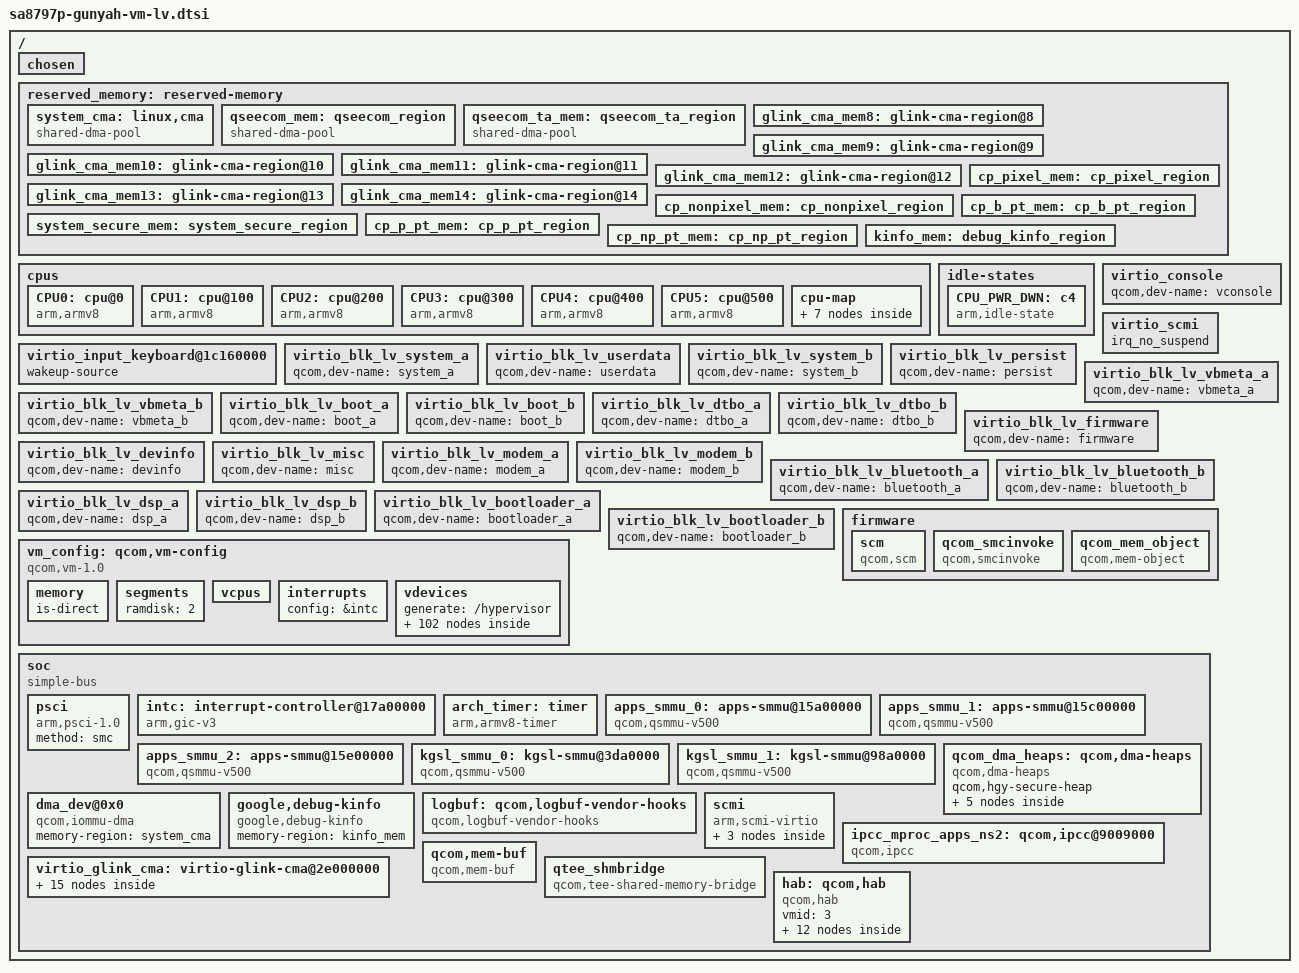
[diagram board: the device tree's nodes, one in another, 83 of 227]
// SPDX-License-Identifier: BSD-3-Clause
/*
 * Copyright (c) Qualcomm Technologies, Inc. and/or its subsidiaries.
 */

#include <dt-bindings/interrupt-controller/arm-gic.h>
#include <dt-bindings/arm/msm/qcom_dma_heap_dt_constants.h>
#include <dt-bindings/mailbox/qcom-ipcc.h>
#include <dt-bindings/soc/qcom,ipcc.h>
#include <dt-bindings/mailbox/qcom-ipcc-sa8797p.h>

/ {
	#address-cells = <0x2>;
	#size-cells = <0x2>;
	qcom,msm-name = "SA_GUNYAH_VM";
	interrupt-parent = <&intc>;

	chosen {
		bootargs = "nokaslr log_buf_len=1M console=hvc0 driver_async_probe=arm-scmi";
	};

	reserved_memory: reserved-memory {
		#address-cells = <2>;
		#size-cells = <2>;
		ranges;

		system_cma: linux,cma {
			compatible = "shared-dma-pool";
			alloc-ranges = <0x0 0x0 0x0 0xffffffff>;
			reusable;
			alignment = <0x0 0x400000>;
			size = <0x0 0x2000000>;
			linux,cma-default;
		};

		qseecom_mem: qseecom_region {
			compatible = "shared-dma-pool";
			alloc-ranges = <0x0 0x00000000 0x0 0xffffffff>;
			reusable;
			alignment = <0x0 0x400000>;
			size = <0x0 0x1400000>;
		};

		qseecom_ta_mem: qseecom_ta_region {
			compatible = "shared-dma-pool";
			alloc-ranges = <0x0 0x00000000 0x0 0xffffffff>;
			reusable;
			alignment = <0x0 0x400000>;
			size = <0x0 0x1000000>;
		};

		glink_cma_mem8: glink-cma-region@8 {
			no-map;
			qcom,label = <0x150>;
		};

		glink_cma_mem9: glink-cma-region@9 {
			no-map;
			qcom,label = <0x151>;
		};

		glink_cma_mem10: glink-cma-region@10 {
			no-map;
			qcom,label = <0x152>;
		};

		glink_cma_mem11: glink-cma-region@11 {
			no-map;
			qcom,label = <0x153>;
		};

		glink_cma_mem12: glink-cma-region@12 {
			no-map;
			qcom,label = <0x154>;
		};

		glink_cma_mem13: glink-cma-region@13 {
			no-map;
			qcom,label = <0x155>;
		};

		glink_cma_mem14: glink-cma-region@14 {
			no-map;
			qcom,label = <0x156>;
		};

		cp_pixel_mem: cp_pixel_region {
			no-map;
			qcom,target-vmid = <0xa>;
			qcom,label = <0xD0A>;
			qcom,unmapped;
		};

		cp_nonpixel_mem: cp_nonpixel_region {
			no-map;
			qcom,target-vmid = <0xb>;
			qcom,label = <0xD0B>;
			qcom,unmapped;
		};

		system_secure_mem: system_secure_region {
			no-map;
			qcom,target-vmid = <0x9>;
			qcom,label = <0xD09>;
			qcom,unmapped;
		};

		cp_b_pt_mem: cp_b_pt_region {
			qcom,label = <0x9D>;
			qcom,secure-pt-reserved;
		};

		cp_p_pt_mem: cp_p_pt_region {
			qcom,label = <0x9E>;
			qcom,secure-pt-reserved;
		};

		cp_np_pt_mem: cp_np_pt_region {
			qcom,label = <0x9F>;
			qcom,secure-pt-reserved;
		};

		kinfo_mem: debug_kinfo_region {
			alloc-ranges = <0x0 0x0 0xffffffff 0xffffffff>;
			size = <0x0 0x1000>;
			no-map;
		};
	};

	cpus {
		#address-cells = <0x2>;
		#size-cells = <0x0>;

		CPU0: cpu@0 {
			compatible = "arm,armv8";
			reg = <0x0 0x0>;
			device_type = "cpu";
			enable-method = "psci";
			cpu-idle-states = <&CPU_PWR_DWN>;
		};

		CPU1: cpu@100 {
			compatible = "arm,armv8";
			reg = <0x0 0x100>;
			device_type = "cpu";
			enable-method = "psci";
			cpu-idle-states = <&CPU_PWR_DWN>;
		};

		CPU2: cpu@200 {
			compatible = "arm,armv8";
			reg = <0x0 0x200>;
			device_type = "cpu";
			enable-method = "psci";
			cpu-idle-states = <&CPU_PWR_DWN>;
		};

		CPU3: cpu@300 {
			compatible = "arm,armv8";
			reg = <0x0 0x300>;
			device_type = "cpu";
			enable-method = "psci";
			cpu-idle-states = <&CPU_PWR_DWN>;
		};

		CPU4: cpu@400 {
			compatible = "arm,armv8";
			reg = <0x0 0x400>;
			device_type = "cpu";
			enable-method = "psci";
			cpu-idle-states = <&CPU_PWR_DWN>;
		};

		CPU5: cpu@500 {
			compatible = "arm,armv8";
			reg = <0x0 0x500>;
			device_type = "cpu";
			enable-method = "psci";
			cpu-idle-states = <&CPU_PWR_DWN>;
		};

		cpu-map {
			cluster0 {
				core0 {
					cpu = <&CPU0>;
				};

				core1 {
					cpu = <&CPU1>;
				};

				core2 {
					cpu = <&CPU2>;
				};

				core3 {
					cpu = <&CPU3>;
				};

				core4 {
					cpu = <&CPU4>;
				};

				core5 {
					cpu = <&CPU5>;
				};
			};
		};
	};

	idle-states {
		CPU_PWR_DWN: c4 { /* C4 */
			compatible = "arm,idle-state";
			idle-state-name = "ret";
			entry-latency-us = <93>;
			exit-latency-us = <129>;
			min-residency-us = <560>;
			arm,psci-suspend-param = <0x00000003>;
			local-timer-stop;
		};
	};

	virtio_input_keyboard@1c160000 {
		wakeup-source;
	};

	virtio_console {
		qcom,dev-name = "vconsole";
	};

	virtio_scmi {
		irq_no_suspend;
	};

	virtio_blk_lv_system_a {
		qcom,dev-name = "system_a";
	};

	virtio_blk_lv_userdata {
		qcom,dev-name = "userdata";
	};

	virtio_blk_lv_system_b {
		qcom,dev-name = "system_b";
	};

	virtio_blk_lv_persist {
		qcom,dev-name = "persist";
	};

	virtio_blk_lv_vbmeta_a {
		qcom,dev-name = "vbmeta_a";
	};

	virtio_blk_lv_vbmeta_b {
		qcom,dev-name = "vbmeta_b";
	};

	virtio_blk_lv_boot_a {
		qcom,dev-name = "boot_a";
	};

	virtio_blk_lv_boot_b {
		qcom,dev-name = "boot_b";
	};

	virtio_blk_lv_dtbo_a {
		qcom,dev-name = "dtbo_a";
	};

	virtio_blk_lv_dtbo_b {
		qcom,dev-name = "dtbo_b";
	};

	virtio_blk_lv_firmware {
		qcom,dev-name = "firmware";
	};

	virtio_blk_lv_devinfo {
		qcom,dev-name = "devinfo";
	};

	virtio_blk_lv_misc {
		qcom,dev-name = "misc";
	};

	virtio_blk_lv_modem_a {
		qcom,dev-name = "modem_a";
	};

	virtio_blk_lv_modem_b {
		qcom,dev-name = "modem_b";
	};

	virtio_blk_lv_bluetooth_a {
		qcom,dev-name = "bluetooth_a";
	};

	virtio_blk_lv_bluetooth_b {
		qcom,dev-name = "bluetooth_b";
	};

	virtio_blk_lv_dsp_a {
		qcom,dev-name = "dsp_a";
	};

	virtio_blk_lv_dsp_b {
		qcom,dev-name = "dsp_b";
	};

	virtio_blk_lv_bootloader_a {
		qcom,dev-name = "bootloader_a";
	};

	virtio_blk_lv_bootloader_b {
		qcom,dev-name = "bootloader_b";
	};

	vm_config: qcom,vm-config {
		compatible = "qcom,vm-1.0";
		vm-type = "aarch64-guest";
		boot-config = "fdt,unified";
		os-type = "linux";
		kernel-entry-segment = "kernel";
		kernel-entry-offset = <0x0 0x0>;
		vendor = "QTI";
		image-name = "qcom,autoghgvmlv";
		qcom,pasid = <0x0 0x2d>;
		qcom,qtee-config-info = "p=3,16,57,77,78,7A,7C,8F,97,159,199,47E,7F1,10C;ta=keymaster64,kmvirt,widevine,pr_3_0,wvqcomkeyprov,drmsampleapp,smpcpyap64,featenabler,auto_test_a,auto_test_b,auto_test_c,auto_test_d,auto_test_e,auto_test_f,auto_test_g,auto_test_h,auto_test_i,auto_test_j,auto_test_k,auto_test_l,auto_test_m,auto_test_n,auto_test_o,auto_test_p,auto_test_320,auto_test_321,auto_test_322,auto_test_323,auto_test_324,apttestapp,apttestapp64,aptcryptotestapp,aptcryptotestapp64,smplserv,tzecotestapp,tzecotestappcbo1,smci_auto_test_1,smci_auto_test_2,smci_auto_test_3,smci_auto_test_4,smci_auto_test_5,smci_auto_test_6,smci_auto_test_7,smci_auto_test_8,smci_auto_test_9,smci_auto_test_10,smci_auto_test_11,smci_auto_test_12,smci_auto_test_13,smci_auto_test_14,smci_auto_test_15,smci_auto_test_16,smci_auto_test_init_crash,smci_auto_test_restartable,smci_auto_test_shutdown_crash,fsp_test_1,fsp_test_2,fsp_test_3,bintestapp64,tzecotestapp1,crypto_testapp,sst_testapp,autosst_testapp,auto_test_unpermitted,5AF8C3E6-D9DF-446E-4FF2-D4D58E8CA49B,19CE19B9-FD73-4262-8553-E5CAC40C895A,C02CAC07-2639-4EF0-BC12-C4AF1FB3E276,15C6B6E4-D083-48E4-8744-4D90A8FF1EF2,CAD10542-34E4-452D-6156-E979AA6E61BC,23914957-C174-4EA6-54D1-DA820F77B4B0,5AF8C3E6-D9DF-446E-4FF2-C3C47D7B938A,CAD10542-34E4-452D-6156-E979AA6E6132,5AF8C3E6-D9DF-446E-4FF2-B2B36C6A8279,FD02C9DA-306C-48C7-A49C-BBD827AE86F0,5AF8C3E6-D9DF-446E-4FF2-D4D58E8CA49B,19CE19B9-FD73-4262-8553-E5CAC40C895A,C02CAC07-2639-4EF0-BC12-C4AF1FB3E276,15C6B6E4-D083-48E4-8744-4D90A8FF1EF2,CAD10542-34E4-452D-6156-E979AA6E61BC,23914957-C174-4EA6-54D1-DA820F77B4B0,5AF8C3E6-D9DF-446E-4FF2-C3C47D7B938A,CAD10542-34E4-452D-6156-E979AA6E6132,5AF8C3E6-D9DF-446E-4FF2-B2B36C6A8279,9824F733-FAC7-502A-81A0-84F6EE3DDACE,20F800CD-0E9B-55CF-A363-1498C26C7100,F577386D-AE4A-5728-921F-F97407BB30A0,3F3E0440-3CD7-5A81-A5DF-6AEB9A0A096C,2DB53398-CA4E-5342-BDED-4544A9039DEA,4C179CF2-22E0-5860-982F-5BBE195F9B0A,CE79BE1D-B0A5-5E69-87C6-6524649F1BEC,F54046B4-11FA-5F76-B4CC-39F58AF4011F,D1DB4C3F-B1E5-5A7F-817E-B49AF2632D1A,2F9D7B61-C79B-5D0B-8FA5-ECCFAE233B7C,220249E5-787C-5F61-B7E6-F69E589F37D6,D4ADCDC0-FF3F-52FA-9267-23971A192A73,0E0F184C-A5F3-543F-9CBF-5104168FE101,1B196214-0457-5774-B768-E8B6F139BECC,AE80F099-54A0-532B-A7BF-58DDB08F2407,E0C6693B-0945-5E72-9385-D71353B81721,10D761D9-037A-51E3-9955-028AF5A77FBA,D9BCD049-9321-52CC-B310-A62789FF3833,3BAA90A5-E4BA-52E9-9A63-EF71FF188B81,71BACACB-52EB-53A5-AA61-510923212679,8A0B3DF4-4947-49E4-85A7-67D7D73B5314,DC0ED4E6-819A-4560-BF13-B4948A7B4379,FF722055-FDC3-4C17-B53D-669E19A358F8,BEE83CCC-0DCC-420F-BAF6-F3F8B48DB22D,534D4152-542D-4353-4C54-2D54412D4552,534D4152-5443-534C-5445-5252544F4F53,534D4152-542D-4353-4C54-2D54412D5355,534D4152-5443-534C-544F-53345041524D,534D4152-542D-4353-4C54-2D54412D5354,534D4152-5443-534C-5443-4C4950415241,534D4152-5443-534C-5443-4C49504F5053,534D4152-542D-4353-4C54-2D54412D3031,534D4152-5443-534C-5441-544346494341,534d4152-5443-534c-5454-434649434132,534D4152-5443-534C-4D4C-54494E535443,534D4152-5443-534C-5347-4C494E535443,534D4152-5443-534C-434C-4F50414E4943,534D4152-5443-4C53-4152-4954484D4554,534D4152-5443-534C-5443-525950544F31,534D4152-5443-534C-5444-415441535431,534D4152-5443-534C-5F54-494D45415049,5AB106AE-7F60-11EA-BC55-0242AC130003,4E3F7FF3-7EDE-45FD-9BAA-7863611E0897,smplap64,ukpapp,unified_key_prov,ukpclnt;";
		qcom,secdomain-ids = <53>;
		qcom,primary-vm-index = <0>;
		vm-attrs = "guest-ram-dump" ,"vpm-virq", "allow-unprotected";
		qcom,peripheral-vmids = <0x9 0xa 0xb>;

		memory {
			#address-cells = <0x2>;
			#size-cells = <0x0>;

			/* The IPA of the Guest regions is placed as IPA=PA */
			is-direct;
		};

		segments {
			ramdisk = <2>;
		};

		vcpus {
			config = "/cpus";
			affinity = "static";
			affinity-map = <0x5 0x4 0x3 0x2 0x1 0x0>;
			sched-priority = <0>;       /* relative to PVM */
			sched-timeslice = <5000>;   /* in us */
		};

		interrupts {
			config = &intc;
		};

		vdevices {
			generate = "/hypervisor";

			minidump {
				vdevice-type = "minidump";
				push-compatible = "qcom,minidump_rm";
				minidump_allowed;
			};

			rm-rpc {
				vdevice-type = "rm-rpc";
				generate = "/hypervisor/qcom,resource-mgr";
				console-dev;
				message-size = <0x000000f0>;
				queue-depth = <0x00000008>;
				qcom,label = <0x1>;
			};

			virtio-mmio@0 {
				vdevice-type = "virtio-mmio";
				generate = "/virtio-mmio";
				peer-default;
				vqs-num = <0x1>;
				push-compatible = "virtio,mmio";
				sync-reset;
				dma-coherent;
				dma_base = <0x0 0x0>;
				memory {
					qcom,label = <0x100>;
					#address-cells = <0x2>;
					allocate-base;
				};
			};

			virtio-mmio@1 {
				vdevice-type = "virtio-mmio";
				patch = "/virtio_blk_lv_devinfo";
				peer-default;
				vqs-num = <0x1>;
				push-compatible = "virtio,mmio";
				sync-reset;
				dma-coherent;
				dma_base = <0x0 0x4000>;
				memory {
					qcom,label = <0x101>;
					#address-cells = <0x2>;
					allocate-base;
				};
			};

			virtio-mmio@2 {
				vdevice-type = "virtio-mmio";
				patch = "/virtio_blk_lv_dsp_a";
				peer-default;
				vqs-num = <0x1>;
				push-compatible = "virtio,mmio";
				sync-reset;
				dma-coherent;
				dma_base = <0x0 0x8000>;
				memory {
					qcom,label = <0x102>;
					#address-cells = <0x2>;
					allocate-base;
				};
			};

			virtio-mmio@3 {
				vdevice-type = "virtio-mmio";
				patch = "/virtio_blk_lv_dsp_b";
				peer-default;
				vqs-num = <0x1>;
				push-compatible = "virtio,mmio";
				sync-reset;
				dma-coherent;
				dma_base = <0x0 0xC000>;
				memory {
					qcom,label = <0x103>;
					#address-cells = <0x2>;
					allocate-base;
				};
			};

			virtio-mmio@4 {
				vdevice-type = "virtio-mmio";
				patch = "/virtio_blk_lv_bootloader_a";
				peer-default;
				vqs-num = <0x1>;
				push-compatible = "virtio,mmio";
				sync-reset;
				dma-coherent;
				dma_base = <0x0 0x10000>;
				memory {
					qcom,label = <0x104>;
					#address-cells = <0x2>;
					allocate-base;
				};
			};

			virtio-mmio@5 {
				vdevice-type = "virtio-mmio";
				patch = "/virtio_blk_lv_bootloader_b";
				peer-default;
				vqs-num = <0x1>;
				push-compatible = "virtio,mmio";
				sync-reset;
				dma-coherent;
				dma_base = <0x0 0x14000>;
				memory {
					qcom,label = <0x105>;
					#address-cells = <0x2>;
					allocate-base;
				};
			};

			virtio-mmio@6 {
				vdevice-type = "virtio-mmio";
				patch = "/virtio_blk_lv_boot_a";
				peer-default;
				vqs-num = <0x1>;
				push-compatible = "virtio,mmio";
				sync-reset;
				dma-coherent;
				dma_base = <0x0 0x18000>;
				memory {
					qcom,label = <0x106>;
					#address-cells = <0x2>;
					allocate-base;
				};
			};

			virtio-mmio@7 {
				vdevice-type = "virtio-mmio";
				patch = "/virtio_blk_lv_boot_b";
				peer-default;
				vqs-num = <0x1>;
				push-compatible = "virtio,mmio";
				sync-reset;
				dma-coherent;
				dma_base = <0x0 0x1C000>;
				memory {
					qcom,label = <0x107>;
					#address-cells = <0x2>;
					allocate-base;
				};
			};

			virtio-mmio@8 {
				vdevice-type = "virtio-mmio";
				patch = "/virtio_blk_lv_bluetooth_a";
				peer-default;
				vqs-num = <0x1>;
				push-compatible = "virtio,mmio";
				sync-reset;
				dma-coherent;
				dma_base = <0x0 0x20000>;
				memory {
					qcom,label = <0x108>;
					#address-cells = <0x2>;
					allocate-base;
				};
			};

			virtio-mmio@9 {
				vdevice-type = "virtio-mmio";
				patch = "/virtio_blk_lv_bluetooth_b";
				peer-default;
				vqs-num = <0x1>;
				push-compatible = "virtio,mmio";
				sync-reset;
				dma-coherent;
				dma_base = <0x0 0x24000>;
				memory {
					qcom,label = <0x109>;
					#address-cells = <0x2>;
					allocate-base;
				};
			};

			virtio-mmio@10 {
				vdevice-type = "virtio-mmio";
				patch = "/virtio_blk_lv_modem_a";
				peer-default;
				vqs-num = <0x1>;
				push-compatible = "virtio,mmio";
				sync-reset;
				dma-coherent;
				dma_base = <0x0 0x28000>;
				memory {
					qcom,label = <0x10A>;
					#address-cells = <0x2>;
					allocate-base;
				};
			};

			virtio-mmio@11 {
				vdevice-type = "virtio-mmio";
				patch = "/virtio_blk_lv_modem_b";
				peer-default;
				vqs-num = <0x1>;
				push-compatible = "virtio,mmio";
				sync-reset;
				dma-coherent;
				dma_base = <0x0 0x2C000>;
				memory {
					qcom,label = <0x10B>;
					#address-cells = <0x2>;
					allocate-base;
				};
			};

			virtio-mmio@12 {
				vdevice-type = "virtio-mmio";
				patch = "/virtio_blk_lv_vbmeta_a";
				peer-default;
				vqs-num = <0x1>;
				push-compatible = "virtio,mmio";
				sync-reset;
				dma-coherent;
				dma_base = <0x0 0x30000>;
				memory {
					qcom,label = <0x10C>;
					#address-cells = <0x2>;
					allocate-base;
				};
			};

			virtio-mmio@13 {
				vdevice-type = "virtio-mmio";
				patch = "/virtio_blk_lv_vbmeta_b";
				peer-default;
				vqs-num = <0x1>;
				push-compatible = "virtio,mmio";
				sync-reset;
				dma-coherent;
				dma_base = <0x0 0x34000>;
				memory {
					qcom,label = <0x10D>;
					#address-cells = <0x2>;
					allocate-base;
				};
			};

			virtio-mmio@14 {
				vdevice-type = "virtio-mmio";
				patch = "/virtio_blk_lv_misc";
				peer-default;
				vqs-num = <0x1>;
				push-compatible = "virtio,mmio";
				sync-reset;
				dma-coherent;
				dma_base = <0x0 0x38000>;
				memory {
					qcom,label = <0x10E>;
					#address-cells = <0x2>;
					allocate-base;
				};
			};

			virtio-mmio@15 {
				vdevice-type = "virtio-mmio";
				patch = "/virtio_blk_lv_persist";
				peer-default;
				vqs-num = <0x1>;
				push-compatible = "virtio,mmio";
				sync-reset;
				dma-coherent;
				dma_base = <0x0 0x3C000>;
				memory {
					qcom,label = <0x10F>;
					#address-cells = <0x2>;
					allocate-base;
				};
			};

			virtio-mmio@16 {
				vdevice-type = "virtio-mmio";
				patch = "/virtio_blk_lv_firmware";
				peer-default;
				vqs-num = <0x1>;
				push-compatible = "virtio,mmio";
				sync-reset;
				dma-coherent;
				dma_base = <0x0 0x40000>;
				memory {
					qcom,label = <0x110>;
					#address-cells = <0x2>;
					allocate-base;
				};
			};

			virtio-mmio@17 {
				vdevice-type = "virtio-mmio";
				patch = "/virtio_blk_lv_userdata";
				peer-default;
				vqs-num = <0x1>;
				push-compatible = "virtio,mmio";
				sync-reset;
				dma-coherent;
				dma_base = <0x0 0x44000>;
				memory {
					qcom,label = <0x111>;
					#address-cells = <0x2>;
					allocate-base;
				};
			};

			virtio-mmio@18 {
				vdevice-type = "virtio-mmio";
				patch = "/virtio_blk_lv_system_a";
				peer-default;
				vqs-num = <0x1>;
				push-compatible = "virtio,mmio";
				sync-reset;
				dma-coherent;
				dma_base = <0x0 0x48000>;
				memory {
					qcom,label = <0x112>;
					#address-cells = <0x2>;
					allocate-base;
				};
			};

			virtio-mmio@19 {
				vdevice-type = "virtio-mmio";
				patch = "/virtio_blk_lv_system_b";
				peer-default;
				vqs-num = <0x1>;
				push-compatible = "virtio,mmio";
				sync-reset;
				dma-coherent;
				dma_base = <0x0 0x4C000>;
				memory {
					qcom,label = <0x113>;
					#address-cells = <0x2>;
					allocate-base;
				};
			};

			virtio-mmio@20 {
				vdevice-type = "virtio-mmio";
				generate = "/virtio-mmio";
				peer-default;
				vqs-num = <0x2>;
				push-compatible = "virtio,mmio";
				sync-reset;
				dma-coherent;
				dma_base = <0x0 0x50000>;
				memory {
					qcom,label = <0x114>;
					#address-cells = <0x2>;
					allocate-base;
				};
			};

			virtio-mmio@21 {
				vdevice-type = "virtio-mmio";
				generate = "/virtio-mmio";
				peer-default;
				vqs-num = <0x2>;
				push-compatible = "virtio,mmio";
				sync-reset;
				dma-coherent;
				dma_base = <0x0 0x58000>;
				memory {
					qcom,label = <0x115>;
					#address-cells = <0x2>;
					allocate-base;
				};
			};

			/*hab 0*/
			virtio-mmio@22 {
				vdevice-type = "virtio-mmio";
				generate = "/virtio-mmio";
				peer-default;
				vqs-num = <0x2>;
				push-compatible = "virtio,mmio";
				sync-reset;
				dma-coherent;
				dma_base = <0x0 0x60000>;
				memory {
					qcom,label = <0x116>;
					#address-cells = <0x2>;
					allocate-base;
				};
			};

			/*hab 1*/
			virtio-mmio@23 {
				vdevice-type = "virtio-mmio";
				generate = "/virtio-mmio";
				peer-default;
				vqs-num = <0x2>;
				push-compatible = "virtio,mmio";
				sync-reset;
				dma-coherent;
				dma_base = <0x0 0x70000>;
				memory {
					qcom,label = <0x117>;
					#address-cells = <0x2>;
					allocate-base;
				};
			};

			/*hab 2*/
			virtio-mmio@24 {
				vdevice-type = "virtio-mmio";
				generate = "/virtio-mmio";
				peer-default;
				vqs-num = <0x8>;
				push-compatible = "virtio,mmio";
				sync-reset;
				dma-coherent;
				dma_base = <0x0 0x80000>;
				memory {
					qcom,label = <0x118>;
					#address-cells = <0x2>;
					allocate-base;
				};
			};

			/*hab 3*/
			virtio-mmio@25 {
				vdevice-type = "virtio-mmio";
				generate = "/virtio-mmio";
				peer-default;
				vqs-num = <0xA>;
				push-compatible = "virtio,mmio";
				sync-reset;
				dma-coherent;
				dma_base = <0x0 0xC0000>;
				memory {
					qcom,label = <0x119>;
					#address-cells = <0x2>;
					allocate-base;
				};
			};

			/*hab 4*/
			virtio-mmio@26 {
				vdevice-type = "virtio-mmio";
				generate = "/virtio-mmio";
				peer-default;
				vqs-num = <0x6>;
				push-compatible = "virtio,mmio";
				sync-reset;
				dma-coherent;
				dma_base = <0x0 0x110000>;
				memory {
					qcom,label = <0x11A>;
					#address-cells = <0x2>;
					allocate-base;
				};
			};

			/*hab 5*/
			virtio-mmio@27 {
				vdevice-type = "virtio-mmio";
				generate = "/virtio-mmio";
				peer-default;
				vqs-num = <0x6>;
				push-compatible = "virtio,mmio";
				sync-reset;
				dma-coherent;
				dma_base = <0x0 0x140000>;
				memory {
					qcom,label = <0x11B>;
					#address-cells = <0x2>;
					allocate-base;
				};
			};

			/*hab 6*/
			virtio-mmio@28 {
				vdevice-type = "virtio-mmio";
				generate = "/virtio-mmio";
				peer-default;
				vqs-num = <0x2>;
				push-compatible = "virtio,mmio";
				sync-reset;
				dma-coherent;
				dma_base = <0x0 0x170000>;
				memory {
					qcom,label = <0x11C>;
					#address-cells = <0x2>;
					allocate-base;
				};
			};

			/*hab 7*/
			virtio-mmio@29 {
				vdevice-type = "virtio-mmio";
				generate = "/virtio-mmio";
				peer-default;
				vqs-num = <0x2>;
				push-compatible = "virtio,mmio";
				sync-reset;
				dma-coherent;
				dma_base = <0x0 0x180000>;
				memory {
					qcom,label = <0x11D>;
					#address-cells = <0x2>;
					allocate-base;
				};
			};

			/*hab 8*/
			virtio-mmio@30 {
				vdevice-type = "virtio-mmio";
				generate = "/virtio-mmio";
				peer-default;
				vqs-num = <0x6>;
				push-compatible = "virtio,mmio";
				sync-reset;
				dma-coherent;
				dma_base = <0x0 0x190000>;
				memory {
					qcom,label = <0x11E>;
					#address-cells = <0x2>;
					allocate-base;
				};
			};

			/* Touch input0 */
			virtio-mmio@31 {
				vdevice-type = "virtio-mmio";
				generate = "/virtio-mmio";
				virtio,device-type = <18>;
				peer-default;
				vqs-num = <0x2>;
				push-compatible = "virtio,mmio";
				sync-reset;
				dma-coherent;
				dma_base = <0x0 0x1C0000>;
				memory {
					qcom,label = <0x11F>;
					#address-cells = <0x2>;
					allocate-base;
				};
			};

			/* keyboard input1 */
			virtio-mmio@32 {
				vdevice-type = "virtio-mmio";
				patch = "/virtio_input_keyboard@1c160000";
				virtio,device-type = <18>;
				peer-default;
				vqs-num = <0x2>;
				push-compatible = "virtio,mmio";
				sync-reset;
				dma-coherent;
				dma_base = <0x0 0x1C4000>;
				memory {
					qcom,label = <0x120>;
					#address-cells = <0x2>;
					allocate-base;
				};
			};

			/* console */
			virtio-mmio@33 {
				vdevice-type = "virtio-mmio";
				patch = "/virtio_console";
				peer-default;
				vqs-num = <0x2>;
				push-compatible = "virtio,mmio";
				sync-reset;
				dma-coherent;
				dma_base = <0x0 0x1C8000>;
				memory {
					qcom,label = <0x121>;
					#address-cells = <0x2>;
					allocate-base;
				};
			};

			/* i2c 0 */
			virtio-mmio@34 {
				vdevice-type = "virtio-mmio";
				generate = "/virtio-mmio";
				peer-default;
				vqs-num = <0x1>;
				push-compatible = "virtio,mmio";
				sync-reset;
				dma-coherent;
				dma_base = <0x0 0x1CC000>;
				memory {
					qcom,label = <0x122>;
					#address-cells = <0x2>;
					allocate-base;
				};
			};

			/* scmi */
			virtio-mmio@35 {
				vdevice-type = "virtio-mmio";
				patch = "/virtio_scmi";
				peer-default;
				vqs-num = <0x2>;
				push-compatible = "virtio,mmio";
				sync-reset;
				dma-coherent;
				dma_base = <0x0 0x1CE000>;
				memory {
					qcom,label = <0x123>;
					#address-cells = <0x2>;
					allocate-base;
				};
			};

			/* dtbo_a */
			virtio-mmio@36 {
				vdevice-type = "virtio-mmio";
				patch = "/virtio_blk_lv_dtbo_a";
				peer-default;
				vqs-num = <0x1>;
				push-compatible = "virtio,mmio";
				sync-reset;
				dma-coherent;
				dma_base = <0x0 0x1D6000>;
				memory {
					qcom,label = <0x124>;
					#address-cells = <0x2>;
					allocate-base;
				};
			};

			/* dtbo_b */
			virtio-mmio@37 {
				vdevice-type = "virtio-mmio";
				patch = "/virtio_blk_lv_dtbo_b";
				peer-default;
				vqs-num = <0x1>;
				push-compatible = "virtio,mmio";
				sync-reset;
				dma-coherent;
				dma_base = <0x0 0x1DA000>;
				memory {
					qcom,label = <0x125>;
					#address-cells = <0x2>;
					allocate-base;
				};
			};

			/* VHAB 9 device */
			virtio-mmio@38 {
				vdevice-type = "virtio-mmio";
				generate = "/virtio-mmio";
				peer-default;
				vqs-num = <0x2>;
				push-compatible = "virtio,mmio";
				sync-reset;
				dma-coherent;
				dma_base = <0x0 0x1DE000>;
				memory {
					qcom,label = <0x126>;
					#address-cells = <0x2>;
					allocate-base;
				};
			};

			/* VHAB 10 device */
			virtio-mmio@39 {
				vdevice-type = "virtio-mmio";
				generate = "/virtio-mmio";
				peer-default;
				vqs-num = <0x4>;
				push-compatible = "virtio,mmio";
				sync-reset;
				dma-coherent;
				dma_base = <0x0 0x20E000>;
				memory {
					qcom,label = <0x127>;
					#address-cells = <0x2>;
					allocate-base;
				};
			};

			/* VHAB 11 device */
			virtio-mmio@40 {
				vdevice-type = "virtio-mmio";
				generate = "/virtio-mmio";
				peer-default;
				vqs-num = <0x2>;
				push-compatible = "virtio,mmio";
				sync-reset;
				dma-coherent;
				dma_base = <0x0 0x23E000>;
				memory {
					qcom,label = <0x128>;
					#address-cells = <0x2>;
					allocate-base;
				};
			};

			/* ssr */
			virtio-mmio@41 {
				vdevice-type = "virtio-mmio";
				generate = "/virtio-mmio";
				peer-default;
				vqs-num = <0x1>;
				push-compatible = "virtio,mmio";
				sync-reset;
				dma-coherent;
				dma_base = <0x0 0x26E000>;
				memory {
					qcom,label = <0x129>;
					#address-cells = <0x2>;
					allocate-base;
				};
			};

			/* glink */
			virtio-mmio@42 {
				vdevice-type = "virtio-mmio";
				patch = "/soc/virtio-glink-cma@2e000000";
				peer-default;
				vqs-num = <0x1>;
				push-compatible = "virtio,mmio";
				sync-reset;
				dma-coherent;
				dma_base = <0x0 0x270000>;
				memory {
					qcom,label = <0x12A>;
					#address-cells = <0x2>;
					allocate-base;
				};
			};

			/* fastrpc */
			virtio-mmio@43 {
				vdevice-type = "virtio-mmio";
				generate = "/virtio-mmio";
				peer-default;
				vqs-num = <0x2>;
				push-compatible = "virtio,mmio";
				sync-reset;
				dma-coherent;
				dma_base = <0x0 0x272000>;
				memory {
					qcom,label = <0x12B>;
					#address-cells = <0x2>;
					allocate-base;
				};
			};

			/* reserved */
			virtio-mmio@44 {
				vdevice-type = "virtio-mmio";
				generate = "/virtio-mmio";
				peer-default;
				vqs-num = <0x2>;
				push-compatible = "virtio,mmio";
				sync-reset;
				dma-coherent;
				dma_base = <0x0 0x276000>;
				memory {
					qcom,label = <0x12C>;
					#address-cells = <0x2>;
					allocate-base;
				};
			};

			hab_virq_dbl13 {
				vdevice-type = "doorbell";
				generate = "/hypervisor/hab_virq_d";
				qcom,label = <0xd>;
				push-compatible = "qcom,msm-virt_irq";
				peer-default;
			};

			hab_virq_dbl14 {
				vdevice-type = "doorbell";
				generate = "/hypervisor/hab_virq_e";
				qcom,label = <0xe>;
				push-compatible = "qcom,msm-virt_irq";
				peer-default;
			};

			hab_virq_dbl15 {
				vdevice-type = "doorbell";
				generate = "/hypervisor/hab_virq_f";
				qcom,label = <0xf>;
				push-compatible = "qcom,msm-virt_irq";
				peer-default;
			};

			swiotlb-shm {
				vdevice-type = "shm";
				generate = "/swiotlb";
				push-compatible = "swiotlb";
				peer-default;
				dma_base = <0x0 0x1100000>;
				memory {
					qcom,label = <0x140>;
					#address-cells = <0x2>;
					allocate-base;
				};
			};

			vsmmu@15a00000 {
				vdevice-type = "vsmmu-v2";
				smmu-handle = <0x15a00000>;
				num-cbs = <0x8>;
				num-smrs = <0x8>;
				patch = "/soc/apps-smmu@15a00000";
			};

			vsmmu@15c00000 {
				vdevice-type = "vsmmu-v2";
				smmu-handle = <0x15c00000>;
				num-cbs = <0xb>;
				num-smrs = <0xb>;
				patch = "/soc/apps-smmu@15c00000";
			};

			vsmmu@15e00000 {
				vdevice-type = "vsmmu-v2";
				smmu-handle = <0x15e00000>;
				num-cbs = <0x1>;
				num-smrs = <0x1>;
				patch = "/soc/apps-smmu@15e00000";
			};

			vsmmu@3da0000 {
				vdevice-type = "vsmmu-v2";
				smmu-handle = <0x3da0000>;
				num-cbs = <0x1>;
				num-smrs = <0x1>;
				patch = "/soc/kgsl-smmu@3da0000";
			};

			vsmmu@98a0000 {
				vdevice-type = "vsmmu-v2";
				smmu-handle = <0x98a0000>;
				num-cbs = <0x1>;
				num-smrs = <0x1>;
				patch = "/soc/kgsl-smmu@98a0000";
			};
		};
	};

	firmware: firmware {
		scm {
			compatible = "qcom,scm";
		};

		qcom_smcinvoke {
			compatible = "qcom,smcinvoke";
		};

		qcom_mem_object {
			compatible = "qcom,mem-object";
		};
	};

	soc: soc { };
};

&soc {
	#address-cells = <1>;
	#size-cells = <1>;
	ranges = <0 0 0 0xffffffff>;
	compatible = "simple-bus";

	psci {
		compatible = "arm,psci-1.0";
		method = "smc";
	};

	intc: interrupt-controller@17a00000 {
		compatible = "arm,gic-v3";
		interrupt-controller;
		#interrupt-cells = <0x3>;
		#redistributor-regions = <1>;
		redistributor-stride = <0x0 0x20000>;
		reg = <0x17a00000 0x10000>,     /* GICD */
		      <0x17a60000 0x240000>;    /* GICR * 18 */
	};

	arch_timer: timer {
		compatible = "arm,armv8-timer";
		always-on;
		interrupts = <GIC_PPI 13 (GIC_CPU_MASK_SIMPLE(8) | IRQ_TYPE_LEVEL_LOW)>,
			     <GIC_PPI 14 (GIC_CPU_MASK_SIMPLE(8) | IRQ_TYPE_LEVEL_LOW)>,
			     <GIC_PPI 11 (GIC_CPU_MASK_SIMPLE(8) | IRQ_TYPE_LEVEL_LOW)>,
			     <GIC_PPI 12 (GIC_CPU_MASK_SIMPLE(8) | IRQ_TYPE_LEVEL_LOW)>;
		clock-frequency = <19200000>;
	};

	apps_smmu_0: apps-smmu@15a00000 {
		/*
		 * reg, #global-interrupts & interrupts  properties will
		 * be added dynamically by bootloader.
		 */
		compatible = "qcom,qsmmu-v500", "qcom,virt-smmu";
		#iommu-cells = <2>;
		qcom,use-3-lvl-tables;
		dma-coherent;
	};

	apps_smmu_1: apps-smmu@15c00000 {
		/*
		 * reg, #global-interrupts & interrupts  properties will
		 * be added dynamically by bootloader.
		 */
		compatible = "qcom,qsmmu-v500", "qcom,virt-smmu";
		#iommu-cells = <2>;
		qcom,use-3-lvl-tables;
		dma-coherent;
	};

	apps_smmu_2: apps-smmu@15e00000 {
		/*
		 * reg, #global-interrupts & interrupts  properties will
		 * be added dynamically by bootloader.
		 */
		compatible = "qcom,qsmmu-v500", "qcom,virt-smmu";
		#iommu-cells = <2>;
		qcom,use-3-lvl-tables;
		dma-coherent;
	};

	kgsl_smmu_0: kgsl-smmu@3da0000 {
		/*
		 * reg, #global-interrupts & interrupts  properties will
		 * be added dynamically by bootloader.
		 */
		compatible = "qcom,qsmmu-v500", "qcom,virt-smmu";
		#iommu-cells = <2>;
		qcom,use-3-lvl-tables;
		dma-coherent;
	};

	kgsl_smmu_1: kgsl-smmu@98a0000 {
		/*
		 * reg, #global-interrupts & interrupts  properties will
		 * be added dynamically by bootloader.
		 */
		compatible = "qcom,qsmmu-v500", "qcom,virt-smmu";
		#iommu-cells = <2>;
		qcom,use-3-lvl-tables;
		dma-coherent;
	};

	qcom_dma_heaps: qcom,dma-heaps {
		compatible = "qcom,dma-heaps";
		qcom,hgy-secure-heap;

		qcom,qseecom {
			qcom,dma-heap-name = "qcom,qseecom";
			qcom,dma-heap-type = <HEAP_TYPE_CMA>;
			memory-region = <&qseecom_mem>;
		};

		qcom,qseecom_ta {
			qcom,dma-heap-name = "qcom,qseecom-ta";
			qcom,dma-heap-type = <HEAP_TYPE_CMA>;
			memory-region = <&qseecom_ta_mem>;
		};

		qcom-cp-pixel {
			qcom,dma-heap-name = "qcom,secure-pixel";
			qcom,dma-heap-type = <HEAP_TYPE_SECURE_CARVEOUT>;
			qcom,token = <0x80000>;
			memory-region = <&cp_pixel_mem>;
		};

		qcom-cp-nonpixel {
			qcom,dma-heap-name = "qcom,secure-non-pixel";
			qcom,dma-heap-type = <HEAP_TYPE_SECURE_CARVEOUT>;
			qcom,token = <0x100000>;
			memory-region = <&cp_nonpixel_mem>;
		};

		qcom-cp-bitstream {
			qcom,dma-heap-name = "system-secure";
			qcom,dma-heap-type = <HEAP_TYPE_SECURE_CARVEOUT>;
			qcom,token = <0x40000>;
			memory-region = <&system_secure_mem>;
		};
	};

	dma_dev@0x0 {
		compatible = "qcom,iommu-dma";
		memory-region = <&system_cma>;
	};

	google,debug-kinfo {
		compatible = "google,debug-kinfo";
		memory-region = <&kinfo_mem>;
	};

	logbuf: qcom,logbuf-vendor-hooks {
		compatible = "qcom,logbuf-vendor-hooks";
	};

	scmi {
		compatible = "arm,scmi-virtio";
		#address-cells = <1>;
		#size-cells = <0>;
		status = "ok";

		scmi_power: protocol@11 {
			reg = <0x11>;
			#power-domain-cells = <1>;
		};

		scmi_perf: protocol@13 {
			reg = <0x13>;
			#power-domain-cells = <1>;
		};

		scmi_reset: protocol@16 {
			reg = <0x16>;
			#reset-cells = <1>;
		};
	};

	ipcc_mproc_apps_ns2: qcom,ipcc@9009000 {
		compatible = "qcom,ipcc";
		reg = <0x9009000 0x1000>;
		interrupts = <GIC_SPI 958 IRQ_TYPE_LEVEL_HIGH>;
		interrupt-controller;
		#interrupt-cells = <3>;
		#mbox-cells = <2>;
	};

	virtio_glink_cma: virtio-glink-cma@2e000000 {
		glink_bridge: virtio-glink-bridge {
			compatible = "virtio,device49162";
			remoteproc_cdsp_glink: glink-edge {
				interrupt-parent = <&ipcc_mproc_apps_ns2>;
				interrupts = <IPCC_MPROC_NSP0 0 IRQ_TYPE_EDGE_RISING>;
				mboxes = <&ipcc_mproc_apps_ns2 IPCC_MPROC_NSP0 0>;
				label = "cdsp";
				qcom,glink-label = "cdsp";
			};

			remoteproc_cdsp1_glink: glink-edge1 {
				interrupt-parent = <&ipcc_mproc_apps_ns2>;
				interrupts = <IPCC_MPROC_NSP1 0 IRQ_TYPE_EDGE_RISING>;
				mboxes = <&ipcc_mproc_apps_ns2 IPCC_MPROC_NSP1 0>;
				label = "cdsp1";
				qcom,glink-label = "cdsp1";
			};

			remoteproc_cdsp2_glink: glink-edge2 {
				interrupt-parent = <&ipcc_mproc_apps_ns2>;
				interrupts = <IPCC_MPROC_NSP2 0 IRQ_TYPE_EDGE_RISING>;
				mboxes = <&ipcc_mproc_apps_ns2 IPCC_MPROC_NSP2 0>;
				label = "cdsp2";
				qcom,glink-label = "cdsp2";
			};

			remoteproc_cdsp3_glink: glink-edge3 {
				interrupt-parent = <&ipcc_mproc_apps_ns2>;
				interrupts = <IPCC_MPROC_NSP3 0 IRQ_TYPE_EDGE_RISING>;
				mboxes = <&ipcc_mproc_apps_ns2 IPCC_MPROC_NSP3 0>;
				label = "cdsp3";
				qcom,glink-label = "cdsp3";
			};

			remoteproc_hpass0_glink: glink-edge4 {
				interrupt-parent = <&ipcc_mproc_apps_ns2>;
				interrupts = <IPCC_MPROC_ADSP0 0 IRQ_TYPE_EDGE_RISING>;
				mboxes = <&ipcc_mproc_apps_ns2 IPCC_MPROC_ADSP0 0>;
				label = "adsp";
				qcom,glink-label = "adsp";
			};

			remoteproc_hpass1_glink: glink-edge5 {
				interrupt-parent = <&ipcc_mproc_apps_ns2>;
				interrupts = <IPCC_MPROC_ADSP1 0 IRQ_TYPE_EDGE_RISING>;
				mboxes = <&ipcc_mproc_apps_ns2 IPCC_MPROC_ADSP1 0>;
				label = "adsp1";
				qcom,glink-label = "adsp1";
			};

			remoteproc_hpass2_glink: glink-edge6 {
				interrupt-parent = <&ipcc_mproc_apps_ns2>;
				interrupts = <IPCC_MPROC_ADSP2  0 IRQ_TYPE_EDGE_RISING>;
				mboxes = <&ipcc_mproc_apps_ns2 IPCC_MPROC_ADSP2 0>;
				label = "adsp2";
				qcom,glink-label = "adsp2";
			};
		};
	};

	qcom,mem-buf {
		compatible = "qcom,mem-buf";
		qcom,mem-buf-capabilities = "consumer";
		qcom,vmid = <53>;
	};

	qtee_shmbridge {
		compatible = "qcom,tee-shared-memory-bridge";
		qcom,custom-bridge-size = <512>;
		qcom,support-hypervisor;
	};

	hab: qcom,hab {
		compatible = "qcom,hab";
		vmid = <3>;

		mmidgrp100: mmidgrp100 {
			grp-start-id = <100>;
			role = "fe";
			remote-vmids = <0>;
			dma-coherent;
		};

		mmidgrp200: mmidgrp200 {
			grp-start-id = <200>;
			role = "fe";
			remote-vmids = <0>;
			dma-coherent;
		};

		mmidgrp300: mmidgrp300 {
			grp-start-id = <300>;
			role = "fe";
			remote-vmids = <0>;
			dma-coherent;
		};

		mmidgrp400: mmidgrp400 {
			grp-start-id = <400>;
			role = "fe";
			remote-vmids = <0>;
			dma-coherent;
		};

		mmidgrp500: mmidgrp500 {
			grp-start-id = <500>;
			role = "fe";
			remote-vmids = <0>;
			dma-coherent;
		};

		mmidgrp600: mmidgrp600 {
			grp-start-id = <600>;
			role = "fe";
			remote-vmids = <0>;
		};

		mmidgrp1400: mmidgrp1400 {
			grp-start-id = <1400>;
			role = "fe";
			remote-vmids = <0>;
		};

		mmidgrp1500: mmidgrp1500 {
			grp-start-id = <1500>;
			role = "fe";
			remote-vmids = <0>;
		};

		mmidgrp1600: mmidgrp1600 {
			grp-start-id = <1600>;
			role = "fe";
			remote-vmids = <0>;
		};

		mmidgrp1700: mmidgrp1700 {
			grp-start-id = <1700>;
			role = "fe";
			remote-vmids = <0>;
			dma-coherent;
		};

		mmidgrp1800: mmidgrp1800 {
			grp-start-id = <1800>;
			role = "fe";
			remote-vmids = <0>;
			dma-coherent;
		};

		mmidgrp1900: mmidgrp1900 {
			grp-start-id = <1900>;
			role = "fe";
			remote-vmids = <0>;
			dma-coherent;
		};
	};
};

&remoteproc_cdsp_glink {
	qcom,fastrpc {
		label = "nsp";
		instance-id = <0>;
		dsp-type = <1>;
	};
};

&remoteproc_cdsp1_glink {
	qcom,fastrpc {
		label = "nsp";
		instance-id = <1>;
		dsp-type = <1>;
	};
};

&remoteproc_cdsp2_glink {
	qcom,fastrpc {
		label = "nsp";
		instance-id = <2>;
		dsp-type = <1>;
	};
};

&remoteproc_cdsp3_glink {
	qcom,fastrpc {
		label = "nsp";
		instance-id = <3>;
		dsp-type = <1>;
	};
};

&remoteproc_hpass0_glink {
	qcom,fastrpc {
		label = "hpass";
		instance-id = <0>;
		dsp-type = <5>;
	};
};

&remoteproc_hpass1_glink {
	qcom,fastrpc {
		label = "hpass";
		instance-id = <1>;
		dsp-type = <5>;
	};
};

&remoteproc_hpass2_glink {
	qcom,fastrpc {
		label = "hpass";
		instance-id = <2>;
		dsp-type = <5>;
	};
};
